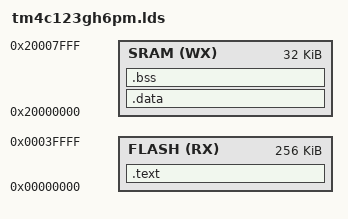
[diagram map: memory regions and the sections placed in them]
/******************************************************************************
 *
 * Default Linker script for the Texas Instruments TM4C123GH6PM
 *
 * This is derived from revision 15071 of the TivaWare Library.
 *
 *****************************************************************************/

MEMORY
{
    FLASH (RX) : ORIGIN = 0x00000000, LENGTH = 0x00040000
    SRAM (WX)  : ORIGIN = 0x20000000, LENGTH = 0x00008000
}

REGION_ALIAS("REGION_TEXT", FLASH);
REGION_ALIAS("REGION_BSS", SRAM);
REGION_ALIAS("REGION_DATA", SRAM);
REGION_ALIAS("REGION_STACK", SRAM);
REGION_ALIAS("REGION_HEAP", SRAM);
REGION_ALIAS("REGION_ARM_EXIDX", FLASH);
REGION_ALIAS("REGION_ARM_EXTAB", FLASH);

/* top end of the stack */
_estack = ORIGIN(SRAM) + LENGTH(SRAM);

/* define output sections */
SECTIONS
{
    /* The program code and other data goes into FLASH */
    .text :
    {
        . = ALIGN(4);
        KEEP(*(.isr_vector)) /* isr vector table */
        *(.text)           /* .text sections (code) */
        *(.text*)          /* .text* sections (code) */
        *(.rodata)         /* .rodata sections (constants, strings, etc.) */
        *(.rodata*)        /* .rodata* sections (constants, strings, etc.) */

        . = ALIGN(4);
        _etext = .;        /* define a global symbol at end of code */
        _sidata = _etext;  /* This is used by the startup in order to initialize the .data secion */
    } >FLASH

    /* This is the initialized data section
    The program executes knowing that the data is in the RAM
    but the loader puts the initial values in the FLASH (inidata).
    It is one task of the startup to copy the initial values from FLASH to RAM. */
    .data : AT ( _sidata )
    {
        . = ALIGN(4);
        _sdata = .;        /* create a global symbol at data start; used by startup code in order to initialise the .data section in RAM */
        *(.data)           /* .data sections */
        *(.data*)          /* .data* sections */

        . = ALIGN(4);
        _edata = .;        /* define a global symbol at data end; used by startup code in order to initialise the .data section in RAM */
    } >SRAM

    /* Uninitialized data section */
    .bss :
    {
        . = ALIGN(4);
        _sbss = .;         /* define a global symbol at bss start; used by startup code */
        *(.bss)
        *(.bss*)
        *(COMMON)

        . = ALIGN(4);
        _ebss = .;         /* define a global symbol at bss end; used by startup code */
    } >SRAM

    .ARM.attributes 0 : { *(.ARM.attributes) }
}

